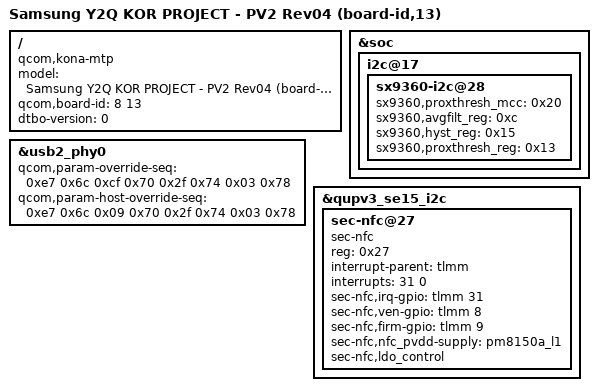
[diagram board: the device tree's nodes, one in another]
/* Copyright (c) 2019, The Linux Foundation. All rights reserved.
 *
 * This program is free software; you can redistribute it and/or modify
 * it under the terms of the GNU General Public License version 2 and
 * only version 2 as published by the Free Software Foundation.
 *
 * This program is distributed in the hope that it will be useful,
 * but WITHOUT ANY WARRANTY; without even the implied warranty of
 * MERCHANTABILITY or FITNESS FOR A PARTICULAR PURPOSE.  See the
 * GNU General Public License for more details.
 */

/dts-v1/;
/plugin/;

#include "../common/kona-sec-common.dtsi"
#include "kona-sec-y2q-r13.dtsi"

/ {
	model = "Samsung Y2Q KOR PROJECT - PV2 Rev04 (board-id,13)";
	compatible = "qcom,kona-mtp", "qcom,kona", "qcom,mtp";
	qcom,board-id = <8 13>;
	dtbo-version = <0>;
};

&soc {
	i2c@17 { /* SW I2C */
		status = "ok";
		sx9360-i2c@28 {
			sx9360,proxthresh_mcc = <0x20>; /* threshhold : 512 */
			sx9360,avgfilt_reg = <0xc>;
			sx9360,hyst_reg = <0x15>;
			sx9360,proxthresh_reg = <0x13>;
		};
	};
};

&usb2_phy0 {
	qcom,param-override-seq =
		<0xe7 0x6c
		 0xcf 0x70
		 0x2f 0x74
		 0x03 0x78>;
	qcom,param-host-override-seq =
		<0xe7 0x6c
		 0x09 0x70
		 0x2f 0x74
		 0x03 0x78>;
};

/* MinsOS 0041: the Samsung NFC of the Japanese units (felica_x1q_r10.dtsi), which share this board-id
 * with Korea and so get this overlay. Same GPIOs as pn547@2B; pn547.c and sec_nfc.c pick one by sales
 * code. No pinctrl: the JPN dtsi's qupv3_se16_spi_nc would park the eSE SPI pins of a Korean unit.
 */
&qupv3_se15_i2c {
	sec-nfc@27 {
		compatible = "sec-nfc";
		reg = <0x27>;
		interrupt-parent = <&tlmm>;
		interrupts = <31 0>;
		sec-nfc,irq-gpio = <&tlmm 31 0>;
		sec-nfc,ven-gpio = <&tlmm 8 0>;
		sec-nfc,firm-gpio = <&tlmm 9 0>;
		sec-nfc,nfc_pvdd-supply = <&pm8150a_l1>;
		sec-nfc,ldo_control;
	};
};
